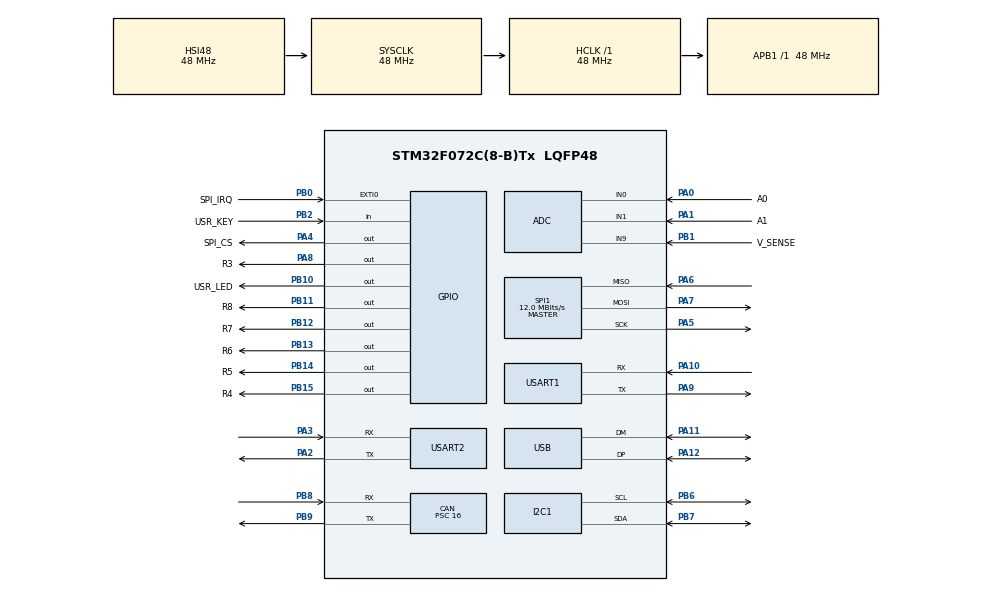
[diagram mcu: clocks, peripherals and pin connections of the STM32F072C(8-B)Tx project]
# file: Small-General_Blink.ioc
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ADC.ContinuousConvMode=DISABLE
CAN.CalculateBaudRate=1000000
CAN.CalculateTimeBit=1000
CAN.CalculateTimeQuantum=333.3333333333333
CAN.Mode=CAN_MODE_NORMAL
CAN.Prescaler=16
CAN.TTCM=DISABLE
Mcu.Family=STM32F0
Mcu.Name=STM32F072C(8-B)Tx
Mcu.Package=LQFP48
NVIC.USB_IRQn=true\:0\:0\:false\:false\:true\:false\:true\:true
PA0.GPIO_Label=A0
PA0.Mode=IN0
PA0.Signal=ADC_IN0
PA1.GPIO_Label=A1
PA1.Mode=IN1
PA1.Signal=ADC_IN1
PA10.Mode=Asynchronous
PA10.Signal=USART1_RX
PA11.Mode=Device
PA11.Signal=USB_DM
PA12.Mode=Device
PA12.Signal=USB_DP
PA13.Mode=Serial_Wire
PA13.Signal=SYS_SWDIO
PA14.Mode=Serial_Wire
PA14.Signal=SYS_SWCLK
PA2.Mode=Asynchronous
PA2.Signal=USART2_TX
PA3.Mode=Asynchronous
PA3.Signal=USART2_RX
PA4.GPIO_Label=SPI_CS
PA4.GPIO_PuPd=GPIO_PULLUP
PA4.GPIO_Speed=GPIO_SPEED_FREQ_HIGH
PA4.PinState=GPIO_PIN_SET
PA4.Signal=GPIO_Output
PA5.Mode=Full_Duplex_Master
PA5.Signal=SPI1_SCK
PA6.Mode=Full_Duplex_Master
PA6.Signal=SPI1_MISO
PA7.Mode=Full_Duplex_Master
PA7.Signal=SPI1_MOSI
PA8.GPIO_Label=R3
PA8.Signal=GPIO_Output
PA9.Mode=Asynchronous
PA9.Signal=USART1_TX
PB0.GPIO_Label=SPI_IRQ
PB0.GPIO_ModeDefaultEXTI=GPIO_MODE_IT_RISING_FALLING
PB0.Signal=GPXTI0
PB1.GPIO_Label=V_SENSE
PB1.Mode=IN9
PB1.Signal=ADC_IN9
PB10.GPIO_Label=USR_LED
PB10.GPIO_ModeDefaultOutputPP=GPIO_MODE_OUTPUT_OD
PB10.GPIO_PuPd=GPIO_NOPULL
PB10.Signal=GPIO_Output
PB11.GPIO_Label=R8
PB11.Signal=GPIO_Output
PB12.GPIO_Label=R7
PB12.Signal=GPIO_Output
PB13.GPIO_Label=R6
PB13.Signal=GPIO_Output
PB14.GPIO_Label=R5
PB14.Signal=GPIO_Output
PB15.GPIO_Label=R4
PB15.Signal=GPIO_Output
PB2.GPIO_Label=USR_KEY
PB2.Signal=GPIO_Input
PB6.Mode=I2C
PB6.Signal=I2C1_SCL
PB7.Mode=I2C
PB7.Signal=I2C1_SDA
PB8.Mode=CAN_Activate
PB8.Signal=CAN_RX
PB9.Mode=CAN_Activate
PB9.Signal=CAN_TX
ProjectManager.HeapSize=0x200
ProjectManager.StackSize=0x400
ProjectManager.TargetToolchain=STM32CubeIDE
RCC.AHBFreq_Value=48000000
RCC.APB1Freq_Value=48000000
RCC.APB1TimFreq_Value=48000000
RCC.HCLKFreq_Value=48000000
RCC.SYSCLKFreq_VALUE=48000000
RCC.SYSCLKSource=RCC_SYSCLKSOURCE_HSI48
SPI1.BaudRatePrescaler=SPI_BAUDRATEPRESCALER_4
SPI1.CalculateBaudRate=12.0 MBits/s
SPI1.Direction=SPI_DIRECTION_2LINES
SPI1.Mode=SPI_MODE_MASTER
SPI1.VirtualType=VM_MASTER
USART1.VirtualMode-Asynchronous=VM_ASYNC
USART2.VirtualMode-Asynchronous=VM_ASYNC
USB_DEVICE.CLASS_NAME_FS=CDC
USB_DEVICE.MANUFACTURER_STRING=NVF2
USB_DEVICE.PRODUCT_STRING_CDC_FS=Small-General
USB_DEVICE.VirtualMode=Cdc
USB_DEVICE.VirtualModeFS=Cdc_FS
VP_ADC_TempSens_Input.Mode=IN-TempSens
VP_USB_DEVICE_VS_USB_DEVICE_CDC_FS.Mode=CDC_FS
board=custom

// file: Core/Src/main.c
/* USER CODE BEGIN Header */
/**
  ******************************************************************************
  * @file           : main.c
  * @brief          : Main program body
  ******************************************************************************
  * @attention
  *
  * Copyright (c) 2024 STMicroelectronics.
  * All rights reserved.
  *
  * This software is licensed under terms that can be found in the LICENSE file
  * in the root directory of this software component.
  * If no LICENSE file comes with this software, it is provided AS-IS.
  *
  ******************************************************************************
  */
/* USER CODE END Header */
#include "main.h"
#include "usb_device.h"

/* USER CODE BEGIN Includes */

#include "usbd_cdc_if.h"
#include "stdbool.h"

/* USER CODE END Includes */

ADC_HandleTypeDef hadc;

CAN_HandleTypeDef hcan;

I2C_HandleTypeDef hi2c1;

SPI_HandleTypeDef hspi1;

UART_HandleTypeDef huart1;
UART_HandleTypeDef huart2;

void SystemClock_Config(void);
static void MX_GPIO_Init(void);
static void MX_ADC_Init(void);
static void MX_CAN_Init(void);
static void MX_I2C1_Init(void);
static void MX_SPI1_Init(void);
static void MX_USART1_UART_Init(void);
static void MX_USART2_UART_Init(void);

int main(void)
{

  /* MCU Configuration--------------------------------------------------------*/

  /* Reset of all peripherals, Initializes the Flash interface and the Systick. */
  HAL_Init();

  /* Configure the system clock */
  SystemClock_Config();

  /* Initialize all configured peripherals */
  MX_GPIO_Init();
  MX_ADC_Init();
  MX_CAN_Init();
  MX_I2C1_Init();
  MX_SPI1_Init();
  MX_USART1_UART_Init();
  MX_USART2_UART_Init();
  MX_USB_DEVICE_Init();
  /* USER CODE BEGIN 2 */

  char usb_tx_buf[1024];
  bool USR_KEY = 0;

  /* USER CODE END 2 */

  /* Infinite loop */
  while (1)
  {

	  USR_KEY = HAL_GPIO_ReadPin(USR_KEY_GPIO_Port, USR_KEY_Pin);

	  if (USR_KEY)
	  {
		  HAL_GPIO_TogglePin(USR_LED_GPIO_Port, USR_LED_Pin);
		  HAL_Delay(500);
	  }
	  else
	  {
		  HAL_Delay(250);
	  }
	  strcpy(usb_tx_buf, "hello world\n");
	  CDC_Transmit_FS((uint8_t*) usb_tx_buf, strlen(usb_tx_buf));

  }
}

void SystemClock_Config(void)
{
  RCC_OscInitTypeDef RCC_OscInitStruct = {0};
  RCC_ClkInitTypeDef RCC_ClkInitStruct = {0};
  RCC_PeriphCLKInitTypeDef PeriphClkInit = {0};

  /** Initializes the RCC Oscillators according to the specified parameters
  * in the RCC_OscInitTypeDef structure.
  */
  RCC_OscInitStruct.OscillatorType = RCC_OSCILLATORTYPE_HSI|RCC_OSCILLATORTYPE_HSI14
                              |RCC_OSCILLATORTYPE_HSI48;
  RCC_OscInitStruct.HSIState = RCC_HSI_ON;
  RCC_OscInitStruct.HSI48State = RCC_HSI48_ON;
  RCC_OscInitStruct.HSI14State = RCC_HSI14_ON;
  RCC_OscInitStruct.HSICalibrationValue = RCC_HSICALIBRATION_DEFAULT;
  RCC_OscInitStruct.HSI14CalibrationValue = 16;
  RCC_OscInitStruct.PLL.PLLState = RCC_PLL_NONE;
  if (HAL_RCC_OscConfig(&RCC_OscInitStruct) != HAL_OK)
  {
    Error_Handler();
  }

  /** Initializes the CPU, AHB and APB buses clocks
  */
  RCC_ClkInitStruct.ClockType = RCC_CLOCKTYPE_HCLK|RCC_CLOCKTYPE_SYSCLK
                              |RCC_CLOCKTYPE_PCLK1;
  RCC_ClkInitStruct.SYSCLKSource = RCC_SYSCLKSOURCE_HSI48;
  RCC_ClkInitStruct.AHBCLKDivider = RCC_SYSCLK_DIV1;
  RCC_ClkInitStruct.APB1CLKDivider = RCC_HCLK_DIV1;

  if (HAL_RCC_ClockConfig(&RCC_ClkInitStruct, FLASH_LATENCY_1) != HAL_OK)
  {
    Error_Handler();
  }
  PeriphClkInit.PeriphClockSelection = RCC_PERIPHCLK_USB|RCC_PERIPHCLK_USART1
                              |RCC_PERIPHCLK_USART2|RCC_PERIPHCLK_I2C1;
  PeriphClkInit.Usart1ClockSelection = RCC_USART1CLKSOURCE_PCLK1;
  PeriphClkInit.Usart2ClockSelection = RCC_USART2CLKSOURCE_PCLK1;
  PeriphClkInit.I2c1ClockSelection = RCC_I2C1CLKSOURCE_HSI;
  PeriphClkInit.UsbClockSelection = RCC_USBCLKSOURCE_HSI48;

  if (HAL_RCCEx_PeriphCLKConfig(&PeriphClkInit) != HAL_OK)
  {
    Error_Handler();
  }
}

static void MX_ADC_Init(void)
{

  ADC_ChannelConfTypeDef sConfig = {0};

  /** Configure the global features of the ADC (Clock, Resolution, Data Alignment and number of conversion)
  */
  hadc.Instance = ADC1;
  hadc.Init.ClockPrescaler = ADC_CLOCK_ASYNC_DIV1;
  hadc.Init.Resolution = ADC_RESOLUTION_12B;
  hadc.Init.DataAlign = ADC_DATAALIGN_RIGHT;
  hadc.Init.ScanConvMode = ADC_SCAN_DIRECTION_FORWARD;
  hadc.Init.EOCSelection = ADC_EOC_SINGLE_CONV;
  hadc.Init.LowPowerAutoWait = DISABLE;
  hadc.Init.LowPowerAutoPowerOff = DISABLE;
  hadc.Init.ContinuousConvMode = DISABLE;
  hadc.Init.DiscontinuousConvMode = DISABLE;
  hadc.Init.ExternalTrigConv = ADC_SOFTWARE_START;
  hadc.Init.ExternalTrigConvEdge = ADC_EXTERNALTRIGCONVEDGE_NONE;
  hadc.Init.DMAContinuousRequests = DISABLE;
  hadc.Init.Overrun = ADC_OVR_DATA_PRESERVED;
  if (HAL_ADC_Init(&hadc) != HAL_OK)
  {
    Error_Handler();
  }

  /** Configure for the selected ADC regular channel to be converted.
  */
  sConfig.Channel = ADC_CHANNEL_0;
  sConfig.Rank = ADC_RANK_CHANNEL_NUMBER;
  sConfig.SamplingTime = ADC_SAMPLETIME_1CYCLE_5;
  if (HAL_ADC_ConfigChannel(&hadc, &sConfig) != HAL_OK)
  {
    Error_Handler();
  }

  /** Configure for the selected ADC regular channel to be converted.
  */
  sConfig.Channel = ADC_CHANNEL_1;
  if (HAL_ADC_ConfigChannel(&hadc, &sConfig) != HAL_OK)
  {
    Error_Handler();
  }

  /** Configure for the selected ADC regular channel to be converted.
  */
  sConfig.Channel = ADC_CHANNEL_9;
  if (HAL_ADC_ConfigChannel(&hadc, &sConfig) != HAL_OK)
  {
    Error_Handler();
  }

  /** Configure for the selected ADC regular channel to be converted.
  */
  sConfig.Channel = ADC_CHANNEL_TEMPSENSOR;
  if (HAL_ADC_ConfigChannel(&hadc, &sConfig) != HAL_OK)
  {
    Error_Handler();
  }

}

static void MX_CAN_Init(void)
{

  hcan.Instance = CAN;
  hcan.Init.Prescaler = 16;
  hcan.Init.Mode = CAN_MODE_NORMAL;
  hcan.Init.SyncJumpWidth = CAN_SJW_1TQ;
  hcan.Init.TimeSeg1 = CAN_BS1_1TQ;
  hcan.Init.TimeSeg2 = CAN_BS2_1TQ;
  hcan.Init.TimeTriggeredMode = DISABLE;
  hcan.Init.AutoBusOff = DISABLE;
  hcan.Init.AutoWakeUp = DISABLE;
  hcan.Init.AutoRetransmission = DISABLE;
  hcan.Init.ReceiveFifoLocked = DISABLE;
  hcan.Init.TransmitFifoPriority = DISABLE;
  if (HAL_CAN_Init(&hcan) != HAL_OK)
  {
    Error_Handler();
  }

}

static void MX_I2C1_Init(void)
{

  hi2c1.Instance = I2C1;
  hi2c1.Init.Timing = 0x2000090E;
  hi2c1.Init.OwnAddress1 = 0;
  hi2c1.Init.AddressingMode = I2C_ADDRESSINGMODE_7BIT;
  hi2c1.Init.DualAddressMode = I2C_DUALADDRESS_DISABLE;
  hi2c1.Init.OwnAddress2 = 0;
  hi2c1.Init.OwnAddress2Masks = I2C_OA2_NOMASK;
  hi2c1.Init.GeneralCallMode = I2C_GENERALCALL_DISABLE;
  hi2c1.Init.NoStretchMode = I2C_NOSTRETCH_DISABLE;
  if (HAL_I2C_Init(&hi2c1) != HAL_OK)
  {
    Error_Handler();
  }

  /** Configure Analogue filter
  */
  if (HAL_I2CEx_ConfigAnalogFilter(&hi2c1, I2C_ANALOGFILTER_ENABLE) != HAL_OK)
  {
    Error_Handler();
  }

  /** Configure Digital filter
  */
  if (HAL_I2CEx_ConfigDigitalFilter(&hi2c1, 0) != HAL_OK)
  {
    Error_Handler();
  }

}

static void MX_SPI1_Init(void)
{

  /* SPI1 parameter configuration*/
  hspi1.Instance = SPI1;
  hspi1.Init.Mode = SPI_MODE_MASTER;
  hspi1.Init.Direction = SPI_DIRECTION_2LINES;
  hspi1.Init.DataSize = SPI_DATASIZE_4BIT;
  hspi1.Init.CLKPolarity = SPI_POLARITY_LOW;
  hspi1.Init.CLKPhase = SPI_PHASE_1EDGE;
  hspi1.Init.NSS = SPI_NSS_SOFT;
  hspi1.Init.BaudRatePrescaler = SPI_BAUDRATEPRESCALER_4;
  hspi1.Init.FirstBit = SPI_FIRSTBIT_MSB;
  hspi1.Init.TIMode = SPI_TIMODE_DISABLE;
  hspi1.Init.CRCCalculation = SPI_CRCCALCULATION_DISABLE;
  hspi1.Init.CRCPolynomial = 7;
  hspi1.Init.CRCLength = SPI_CRC_LENGTH_DATASIZE;
  hspi1.Init.NSSPMode = SPI_NSS_PULSE_ENABLE;
  if (HAL_SPI_Init(&hspi1) != HAL_OK)
  {
    Error_Handler();
  }

}

static void MX_USART1_UART_Init(void)
{

  huart1.Instance = USART1;
  huart1.Init.BaudRate = 38400;
  huart1.Init.WordLength = UART_WORDLENGTH_8B;
  huart1.Init.StopBits = UART_STOPBITS_1;
  huart1.Init.Parity = UART_PARITY_NONE;
  huart1.Init.Mode = UART_MODE_TX_RX;
  huart1.Init.HwFlowCtl = UART_HWCONTROL_NONE;
  huart1.Init.OverSampling = UART_OVERSAMPLING_16;
  huart1.Init.OneBitSampling = UART_ONE_BIT_SAMPLE_DISABLE;
  huart1.AdvancedInit.AdvFeatureInit = UART_ADVFEATURE_NO_INIT;
  if (HAL_UART_Init(&huart1) != HAL_OK)
  {
    Error_Handler();
  }

}

static void MX_USART2_UART_Init(void)
{

  huart2.Instance = USART2;
  huart2.Init.BaudRate = 38400;
  huart2.Init.WordLength = UART_WORDLENGTH_8B;
  huart2.Init.StopBits = UART_STOPBITS_1;
  huart2.Init.Parity = UART_PARITY_NONE;
  huart2.Init.Mode = UART_MODE_TX_RX;
  huart2.Init.HwFlowCtl = UART_HWCONTROL_NONE;
  huart2.Init.OverSampling = UART_OVERSAMPLING_16;
  huart2.Init.OneBitSampling = UART_ONE_BIT_SAMPLE_DISABLE;
  huart2.AdvancedInit.AdvFeatureInit = UART_ADVFEATURE_NO_INIT;
  if (HAL_UART_Init(&huart2) != HAL_OK)
  {
    Error_Handler();
  }

}

static void MX_GPIO_Init(void)
{
  GPIO_InitTypeDef GPIO_InitStruct = {0};

  /* GPIO Ports Clock Enable */
  __HAL_RCC_GPIOA_CLK_ENABLE();
  __HAL_RCC_GPIOB_CLK_ENABLE();

  /*Configure GPIO pin Output Level */
  HAL_GPIO_WritePin(SPI_CS_GPIO_Port, SPI_CS_Pin, GPIO_PIN_SET);

  /*Configure GPIO pin Output Level */
  HAL_GPIO_WritePin(GPIOB, USR_LED_Pin|R8_Pin|R7_Pin|R6_Pin
                          |R5_Pin|R4_Pin, GPIO_PIN_RESET);

  /*Configure GPIO pin Output Level */
  HAL_GPIO_WritePin(R3_GPIO_Port, R3_Pin, GPIO_PIN_RESET);

  /*Configure GPIO pin : SPI_CS_Pin */
  GPIO_InitStruct.Pin = SPI_CS_Pin;
  GPIO_InitStruct.Mode = GPIO_MODE_OUTPUT_PP;
  GPIO_InitStruct.Pull = GPIO_PULLUP;
  GPIO_InitStruct.Speed = GPIO_SPEED_FREQ_HIGH;
  HAL_GPIO_Init(SPI_CS_GPIO_Port, &GPIO_InitStruct);

  /*Configure GPIO pin : SPI_IRQ_Pin */
  GPIO_InitStruct.Pin = SPI_IRQ_Pin;
  GPIO_InitStruct.Mode = GPIO_MODE_IT_RISING_FALLING;
  GPIO_InitStruct.Pull = GPIO_NOPULL;
  HAL_GPIO_Init(SPI_IRQ_GPIO_Port, &GPIO_InitStruct);

  /*Configure GPIO pin : USR_KEY_Pin */
  GPIO_InitStruct.Pin = USR_KEY_Pin;
  GPIO_InitStruct.Mode = GPIO_MODE_INPUT;
  GPIO_InitStruct.Pull = GPIO_NOPULL;
  HAL_GPIO_Init(USR_KEY_GPIO_Port, &GPIO_InitStruct);

  /*Configure GPIO pin : USR_LED_Pin */
  GPIO_InitStruct.Pin = USR_LED_Pin;
  GPIO_InitStruct.Mode = GPIO_MODE_OUTPUT_OD;
  GPIO_InitStruct.Pull = GPIO_NOPULL;
  GPIO_InitStruct.Speed = GPIO_SPEED_FREQ_LOW;
  HAL_GPIO_Init(USR_LED_GPIO_Port, &GPIO_InitStruct);

  /*Configure GPIO pins : R8_Pin R7_Pin R6_Pin R5_Pin
                           R4_Pin */
  GPIO_InitStruct.Pin = R8_Pin|R7_Pin|R6_Pin|R5_Pin
                          |R4_Pin;
  GPIO_InitStruct.Mode = GPIO_MODE_OUTPUT_PP;
  GPIO_InitStruct.Pull = GPIO_NOPULL;
  GPIO_InitStruct.Speed = GPIO_SPEED_FREQ_LOW;
  HAL_GPIO_Init(GPIOB, &GPIO_InitStruct);

  /*Configure GPIO pin : R3_Pin */
  GPIO_InitStruct.Pin = R3_Pin;
  GPIO_InitStruct.Mode = GPIO_MODE_OUTPUT_PP;
  GPIO_InitStruct.Pull = GPIO_NOPULL;
  GPIO_InitStruct.Speed = GPIO_SPEED_FREQ_LOW;
  HAL_GPIO_Init(R3_GPIO_Port, &GPIO_InitStruct);

}

void Error_Handler(void)
{
  __disable_irq();
  while (1)
  {
  }
}
